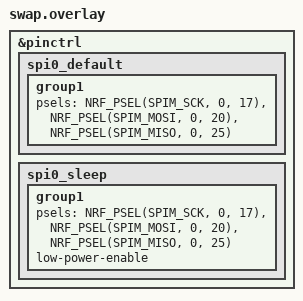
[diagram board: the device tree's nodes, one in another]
/*
 * Обмен SCK и MOSI: `make display-test SWAP=1`. На 4-контактном разъёме
 * SDA (P0.17) уходит в MOSI, SCL (P0.20) в SCK; если у клона маркировка
 * разъёма обратная, линии надо поменять.
 */

#include <zephyr/dt-bindings/pinctrl/nrf-pinctrl.h>

&pinctrl {
    spi0_default {
        group1 {
            psels = <NRF_PSEL(SPIM_SCK, 0, 17)>,
                <NRF_PSEL(SPIM_MOSI, 0, 20)>,
                <NRF_PSEL(SPIM_MISO, 0, 25)>;
        };
    };
    spi0_sleep {
        group1 {
            psels = <NRF_PSEL(SPIM_SCK, 0, 17)>,
                <NRF_PSEL(SPIM_MOSI, 0, 20)>,
                <NRF_PSEL(SPIM_MISO, 0, 25)>;
            low-power-enable;
        };
    };
};
